VERSION ""

NS_ :

BS_:

BU_: PID

VAL_TABLE_ OnOff 1 "on" 0 "off" ;

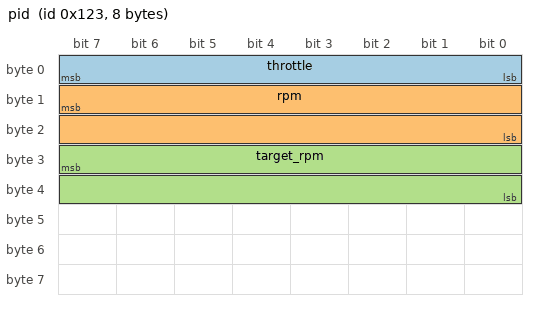
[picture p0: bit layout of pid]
BO_ 291 pid: 8 PID
 SG_ throttle : 7|8@0+ (1,0) [0|0] "" Vector__XXX
 SG_ rpm : 15|16@0+ (1,0) [0|0] "" Vector__XXX
 SG_ target_rpm : 31|16@0+ (1,0) [0|0] "" Vector__XXX
